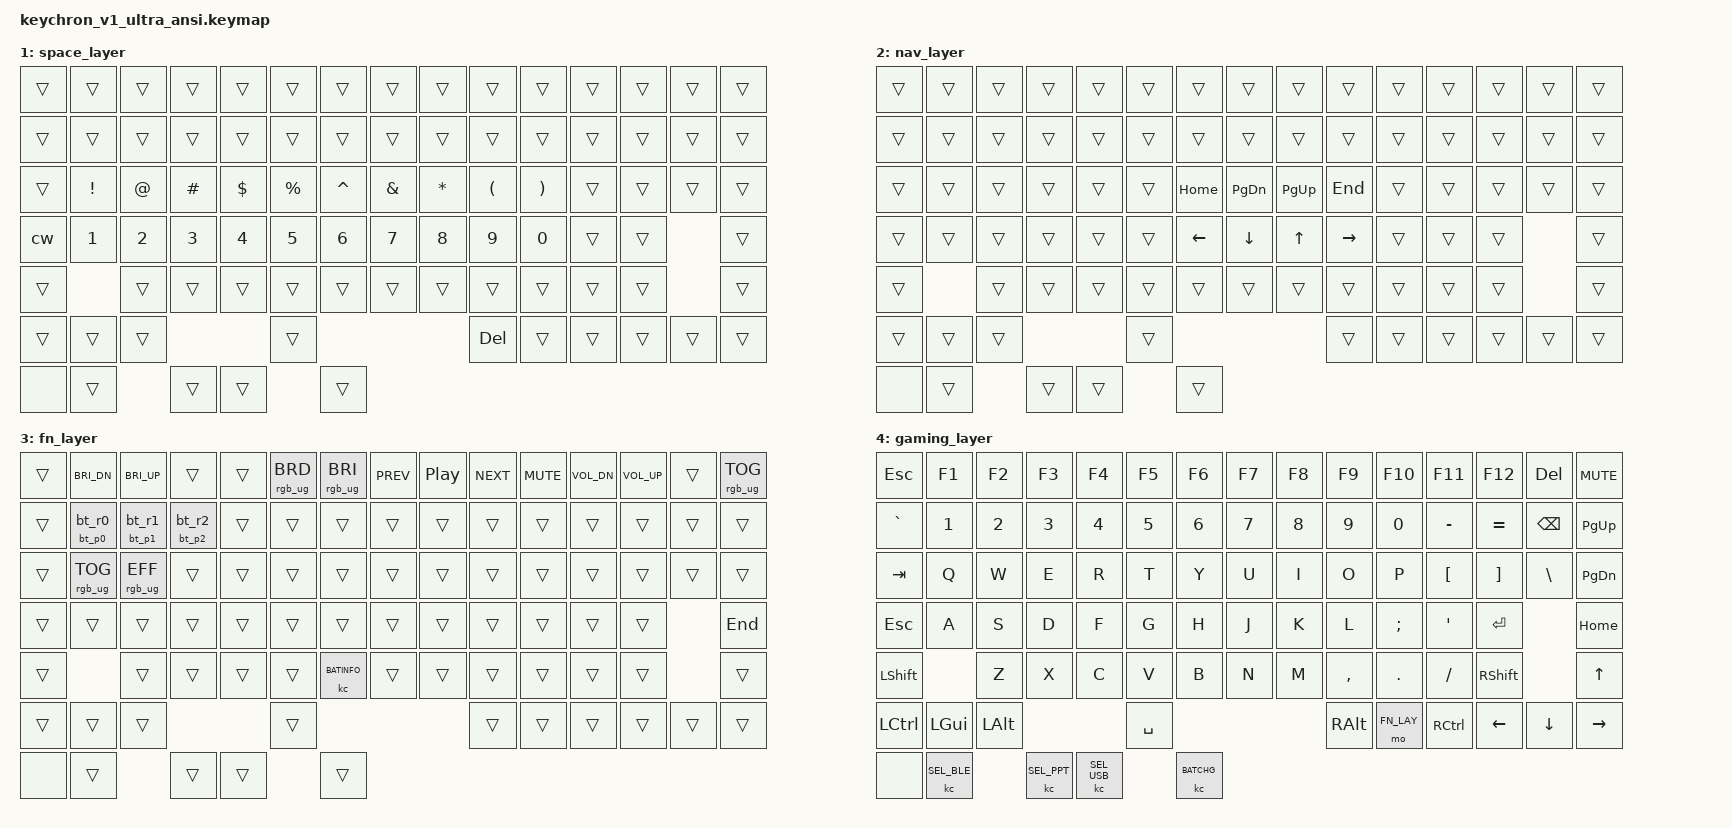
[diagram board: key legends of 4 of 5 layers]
#include <behaviors.dtsi>
#include <dt-bindings/zmk/keys.h>
#include <dt-bindings/zmk/bt.h>
#include <dt-bindings/zmk/rgb.h>
#include <dt-bindings/zmk/outputs.h>
#include <dt-bindings/zmk/keychron.h>
#include "homerow_mods.dtsi"

#define BASE_LAY 0
#define SPC_LAY 1
#define NAV_LAY 2
#define FN_LAY 3
#define GAME_LAY 4

/ {
    macros {
        bt_p0: bt_pair_0 { compatible = "zmk,behavior-macro"; #binding-cells = <0>; bindings = <&kc BT_PAIR 0>; };
        bt_p1: bt_pair_1 { compatible = "zmk,behavior-macro"; #binding-cells = <0>; bindings = <&kc BT_PAIR 1>; };
        bt_p2: bt_pair_2 { compatible = "zmk,behavior-macro"; #binding-cells = <0>; bindings = <&kc BT_PAIR 2>; };

        bt_r0: bt_recon_0 { compatible = "zmk,behavior-macro"; #binding-cells = <0>; bindings = <&kc BT_SEL 0>; };
        bt_r1: bt_recon_1 { compatible = "zmk,behavior-macro"; #binding-cells = <0>; bindings = <&kc BT_SEL 1>; };
        bt_r2: bt_recon_2 { compatible = "zmk,behavior-macro"; #binding-cells = <0>; bindings = <&kc BT_SEL 2>; };
    };

    behaviors {
        slt: space_layer_tap {
            compatible = "zmk,behavior-hold-tap";
            label = "SPACE_LAYER_TAP";
            #binding-cells = <2>;
            flavor = "tap-preferred";
            tapping-term-ms = <200>;
            quick-tap-ms = <175>;
            bindings = <&mo>, <&kp>;
        };

        tlt: thumb_layer_tap {
            compatible = "zmk,behavior-hold-tap";
            label = "THUMB_LAYER_TAP";
            #binding-cells = <2>;
            flavor = "balanced";
            tapping-term-ms = <280>;
            quick-tap-ms = <200>;
            bindings = <&mo>, <&kp>;
        };

        shift_z: tap_dance_mod_tap_z {
            compatible = "zmk,behavior-hold-tap";
            #binding-cells = <2>;
            flavor = "balanced";
            tapping-term-ms = <200>;
            quick-tap-ms = <175>;
            bindings = <&kp>, <&kp>;
        };

        rgb_encoder: rgb_encoder {
            compatible = "zmk,behavior-sensor-rotate";
            #sensor-binding-cells = <0>;
            bindings = <&rgb_ug RGB_BRI>, <&rgb_ug RGB_BRD>;
            tap-ms =<20>;
        };


        // Bluetooth behaviors
        // Hold-tap always requires two binding cells, even when its wrapped
        // zero-argument macros do not use them.
        bt_slot0: bt_slot0 {
            compatible = "zmk,behavior-hold-tap";
            #binding-cells = <2>;
            flavor = "tap-preferred";
            tapping-term-ms = <3000>;
            bindings = <&bt_p0>, <&bt_r0>;
        };

        bt_slot1: bt_slot1 {
            compatible = "zmk,behavior-hold-tap";
            #binding-cells = <2>;
            flavor = "tap-preferred";
            tapping-term-ms = <3000>;
            bindings = <&bt_p1>, <&bt_r1>;
        };

        bt_slot2: bt_slot2 {
            compatible = "zmk,behavior-hold-tap";
            #binding-cells = <2>;
            flavor = "tap-preferred";
            tapping-term-ms = <3000>;
            bindings = <&bt_p2>, <&bt_r2>;
        };
    };

    keymap {
        compatible = "zmk,keymap";

        // =========================================================================
        // LAYER 0: BASE HRM
        // Replace the A,S,D,F and J,K,L,SEMI with your hml/hmr behaviors
        // =========================================================================
        base_layer {
            bindings = <
    &kp ESC     &kp F1      &kp F2      &kp F3       &kp F4       &kp F5     &kp F6     &kp F7       &kp F8       &kp F9      &kp F10        &kp F11    &kp F12    &kp DEL    &kp C_MUTE
    &kp GRAVE   &kp N1      &kp N2      &kp N3       &kp N4       &kp N5     &kp N6     &kp N7       &kp N8       &kp N9      &kp N0         &kp MINUS  &kp EQUAL  &kp BSPC   &kp PG_UP
    &kp TAB     &kp Q       &kp W       &kp E        &kp R        &kp T      &kp Y      &kp U        &kp I        &kp O       &kp P          &kp LBKT   &kp RBKT   &kp BSLH   &kp PG_DN
    &kp ESC     HRM_LEFT                                      &kp G      &kp H      HRM_RIGHT                                      &kp SQT    &kp RET               &kp HOME
    &kp LSHFT           &kp Z       &kp X         &kp C       &kp V     &kp B      &kp N          &kp M      &kp COMMA    &kp DOT       &kp FSLH    &kp RSHFT                &kp UP
    &kp LCTRL  &kp LGUI   &tlt NAV_LAY TAB                       &slt SPC_LAY SPACE                                       &kp BSPC      &mo FN_LAY  &kp RCTRL &kp LEFT   &kp DOWN   &kp RIGHT
    // Keychron Hardware Control
    &mo GAME_LAY      &kc SEL_BLE           &kc SEL_PPT           &kc SEL_USB           &kc BATCHG
            >;
            sensor-bindings = <&inc_dec_kp C_VOL_UP C_VOL_DN>;
        };

        // =========================================================================
        // SPACE / NUMBER LAYER
        // Accessible by holding Space (or whichever trigger you choose)
        // =========================================================================
        space_layer {
            bindings = <
    &trans     &trans     &trans     &trans     &trans     &trans     &trans     &trans     &trans     &trans     &trans     &trans     &trans     &trans     &trans
    &trans     &trans     &trans     &trans     &trans     &trans     &trans     &trans     &trans     &trans     &trans     &trans     &trans     &trans     &trans
    &trans     &kp EXCL   &kp AT     &kp HASH   &kp DLLR   &kp PRCNT  &kp CARET  &kp AMPS   &kp STAR   &kp LPAR   &kp RPAR   &trans     &trans     &trans     &trans
    &cw        &kp N1     &kp N2     &kp N3     &kp N4     &kp N5     &kp N6     &kp N7     &kp N8     &kp N9     &kp N0     &trans     &trans                &trans
    &trans                &trans     &trans     &trans     &trans     &trans     &trans     &trans     &trans     &trans     &trans     &trans                &trans
    &trans     &trans     &trans                           &trans                                      &kp DEL    &trans     &trans     &trans     &trans     &trans
    // Keychron Hardware Control
    &none      &trans           &trans           &trans           &trans
            >;
        };

        // =========================================================================
        // NAV LAYER
        // Accessible by holding LALT
        // =========================================================================
        nav_layer {
            bindings = <
    &trans     &trans     &trans     &trans     &trans     &trans     &trans     &trans     &trans     &trans     &trans     &trans     &trans     &trans     &trans
    &trans     &trans     &trans     &trans     &trans     &trans     &trans     &trans     &trans     &trans     &trans     &trans     &trans     &trans     &trans
    &trans     &trans     &trans     &trans     &trans     &trans     &kp HOME   &kp PG_DN  &kp PG_UP  &kp END    &trans     &trans     &trans     &trans     &trans
    &trans     &trans     &trans     &trans     &trans     &trans     &kp LEFT   &kp DOWN   &kp UP     &kp RIGHT  &trans     &trans     &trans                &trans
    &trans                &trans     &trans     &trans     &trans     &trans     &trans     &trans     &trans     &trans     &trans     &trans                &trans
    &trans     &trans     &trans                           &trans                                      &trans     &trans     &trans     &trans     &trans     &trans
    // Keychron Hardware Control
    &none      &trans           &trans           &trans           &trans
            >;
        };

        // =========================================================================
        // FN LAYER
        // Media controls, RGB controls, Bluetooth Profiles
        // =========================================================================
        fn_layer {
            bindings = <
    &trans     &kp C_BRI_DN    &kp C_BRI_UP    &trans       &trans   &rgb_ug RGB_BRD &rgb_ug RGB_BRI  &kp C_PREV &kp C_PP   &kp C_NEXT &kp C_MUTE &kp C_VOL_DN &kp C_VOL_UP &trans &rgb_ug RGB_TOG
    &trans     &bt_slot0 0 0   &bt_slot1 0 0   &bt_slot2 0 0 &trans   &trans          &trans           &trans     &trans     &trans     &trans     &trans     &trans     &trans &trans
    &trans     &rgb_ug RGB_TOG &rgb_ug RGB_EFF &trans       &trans   &trans          &trans           &trans     &trans     &trans     &trans     &trans     &trans     &trans     &trans
    &trans     &trans     &trans     &trans     &trans     &trans    &trans          &trans           &trans     &trans     &trans     &trans     &trans                &kp END
    &trans                &trans     &trans     &trans     &trans    &kc BATINFO &trans     &trans     &trans     &trans     &trans     &trans &trans
    &trans     &trans     &trans                           &trans                                      &trans     &trans     &trans     &trans     &trans     &trans
    // Keychron Hardware Control
    &none      &trans           &trans           &trans           &trans
            >;
            sensor-bindings = <&rgb_encoder>;
        };

        // =========================================================================
        // GAMING LAYER
        // Standard QWERTY with NO hold-taps, ensuring zero input delay
        // =========================================================================
        // TODO: Fix FN layer not working in Gaming Layer
        gaming_layer {
            bindings = <
    &kp ESC    &kp F1     &kp F2     &kp F3     &kp F4     &kp F5     &kp F6     &kp F7     &kp F8     &kp F9     &kp F10    &kp F11    &kp F12    &kp DEL    &kp C_MUTE
    &kp GRAVE  &kp N1     &kp N2     &kp N3     &kp N4     &kp N5     &kp N6     &kp N7     &kp N8     &kp N9     &kp N0     &kp MINUS  &kp EQUAL  &kp BSPC   &kp PG_UP
    &kp TAB    &kp Q      &kp W      &kp E      &kp R      &kp T      &kp Y      &kp U      &kp I      &kp O      &kp P      &kp LBKT   &kp RBKT   &kp BSLH   &kp PG_DN
    &kp ESC    &kp A      &kp S      &kp D      &kp F      &kp G      &kp H      &kp J      &kp K      &kp L      &kp SEMI   &kp SQT    &kp RET               &kp HOME
    &kp LSHFT             &kp Z      &kp X      &kp C      &kp V      &kp B      &kp N      &kp M      &kp COMMA  &kp DOT    &kp FSLH   &kp RSHFT     &kp UP
    &kp LCTRL  &kp LGUI   &kp LALT                         &kp SPACE                                   &kp RALT   &mo FN_LAY &kp RCTRL    &kp LEFT   &kp DOWN   &kp RIGHT
    // Keychron Hardware Control
    &none      &kc SEL_BLE           &kc SEL_PPT           &kc SEL_USB           &kc BATCHG
            >;
            sensor-bindings = <&inc_dec_kp C_VOL_UP C_VOL_DN>;
        };
    };
};
